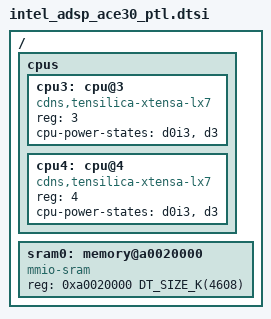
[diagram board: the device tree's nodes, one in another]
/*
 * Copyright (c) 2024 Intel Corporation
 *
 * SPDX-License-Identifier: Apache-2.0
 */

#include <xtensa/intel/intel_adsp_ace30.dtsi>

/ {
	cpus {
		cpu3: cpu@3 {
			device_type = "cpu";
			compatible = "cdns,tensilica-xtensa-lx7";
			reg = <3>;
			cpu-power-states = <&d0i3 &d3>;
		};

		cpu4: cpu@4 {
			device_type = "cpu";
			compatible = "cdns,tensilica-xtensa-lx7";
			reg = <4>;
			cpu-power-states = <&d0i3 &d3>;
		};
	};

	sram0: memory@a0020000 {
		device_type = "memory";
		compatible = "mmio-sram";
		reg = <0xa0020000 DT_SIZE_K(4608)>;
	};
};
